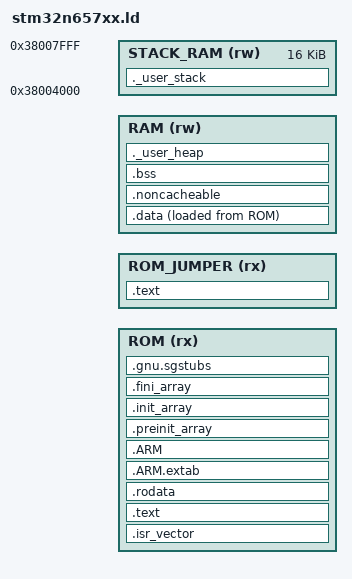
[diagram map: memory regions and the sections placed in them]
/*
******************************************************************************
**
** @file        : stm32n657xx.ld
**
** @author      : GPM Application Team
**
** @brief       : Linker script for STM32N657XX Device from STM32N6 series
**
**                Set heap size, stack size and stack location according
**                to application requirements.
**
**                Set memory bank area and size if external memory is used
**
**  Target      : STMicroelectronics STM32
**
**  Distribution: The file is distributed as is, without any warranty
**                of any kind.
**
******************************************************************************
** @attention
**
** Copyright (c) 2024 STMicroelectronics.
** All rights reserved.
**
** This software is licensed under terms that can be found in the LICENSE file
** in the root directory of this software component.
** If no LICENSE file comes with this software, it is provided AS-IS.
**
******************************************************************************
*/

#include "region_defs.h"

/* Entry Point */
ENTRY(Reset_Handler)

/* Highest address of the user mode stack */
_estack = ORIGIN(STACK_RAM) + LENGTH(STACK_RAM); /* end of "RAM" Ram type memory */
_sstack = _estack - _Min_Stack_Size;

_Min_Heap_Size = BL2_HEAP_SIZE; /* required amount of heap */
_Min_Stack_Size = BL2_MSP_STACK_SIZE; /* required amount of stack */

/* Memories definition */
MEMORY
{
  ROM  (rx)  : ORIGIN = BL2_CODE_START, LENGTH = BL2_CODE_SIZE
  ROM_JUMPER  (rx)  : ORIGIN = BL2_JUMP_CODE_START, LENGTH = BL2_JUMP_CODE_SIZE
  RAM  (rw)  : ORIGIN = BL2_DATA_START, LENGTH = BL2_DATA_SIZE
  STACK_RAM  (rw)  : ORIGIN = 0x38004000, LENGTH = 0x4000
}

/* Sections */
SECTIONS
{
  /* The startup code into "RAM" Ram type memory */
  .isr_vector :
  {
    . = ALIGN(4);
    KEEP(*(.isr_vector)) /* Startup code */
    . = ALIGN(4);
  } >ROM

  .text :
  {
    KEEP(*(.BL2_Jump_Code))
    KEEP(*(.BL2_Jump_Data))
    *stm32n6xx_hal_cortex.o (.text* .rodata*)
    *stm32n6xx_hal_mce.o (.text* .rodata*)
    *stm32n6xx_hal_bsec.o (.text* .rodata*)
    *low_level_mce.o (.text* .rodata*)
    *low_level_otp.o (.text* .rodata*)
    KEEP(*(.BL2_Error_Code))
  } >ROM_JUMPER

  /* The program code and other data into "RAM" Ram type memory */
  .text :
  {
    . = ALIGN(4);
    *(.text)           /* .text sections (code) */
    *(.text*)          /* .text* sections (code) */
    *(.glue_7)         /* glue arm to thumb code */
    *(.glue_7t)        /* glue thumb to arm code */
    *(.eh_frame)
    *(.RamFunc)        /* .RamFunc sections */
    *(.RamFunc*)       /* .RamFunc* sections */

    KEEP (*(.init))
    KEEP (*(.fini))

    . = ALIGN(4);
    _etext = .;        /* define a global symbols at end of code */
  } >ROM

  /* Constant data into "RAM" Ram type memory */
  .rodata :
  {
    . = ALIGN(4);
    *(.rodata)         /* .rodata sections (constants, strings, etc.) */
    *(.rodata*)        /* .rodata* sections (constants, strings, etc.) */
    . = ALIGN(4);
  } >ROM

  .ARM.extab   (READONLY) : /* The READONLY keyword is only supported in GCC11 and later, remove it if using GCC10 or earlier. */
   {
    . = ALIGN(4);
    *(.ARM.extab* .gnu.linkonce.armextab.*)
    . = ALIGN(4);
  } >ROM

  .ARM (READONLY) : /* The READONLY keyword is only supported in GCC11 and later, remove it if using GCC10 or earlier. */
   {
    . = ALIGN(4);
    __exidx_start = .;
    *(.ARM.exidx*)
    __exidx_end = .;
    . = ALIGN(4);
  } >ROM

  .preinit_array     (READONLY) : /* The READONLY keyword is only supported in GCC11 and later, remove it if using GCC10 or earlier. */
  {
    . = ALIGN(4);
    PROVIDE_HIDDEN (__preinit_array_start = .);
    KEEP (*(.preinit_array*))
    PROVIDE_HIDDEN (__preinit_array_end = .);
    . = ALIGN(4);
  } >ROM

  .init_array (READONLY) : /* The READONLY keyword is only supported in GCC11 and later, remove it if using GCC10 or earlier. */
  {
    . = ALIGN(4);
    PROVIDE_HIDDEN (__init_array_start = .);
    KEEP (*(SORT(.init_array.*)))
    KEEP (*(.init_array*))
    PROVIDE_HIDDEN (__init_array_end = .);
    . = ALIGN(4);
  } >ROM

  .fini_array (READONLY) : /* The READONLY keyword is only supported in GCC11 and later, remove it if using GCC10 or earlier. */
  {
    . = ALIGN(4);
    PROVIDE_HIDDEN (__fini_array_start = .);
    KEEP (*(SORT(.fini_array.*)))
    KEEP (*(.fini_array*))
    PROVIDE_HIDDEN (__fini_array_end = .);
    . = ALIGN(4);
  } >ROM

  /* Used by the startup to initialize data */
  _sidata = LOADADDR(.data);

  /* Initialized data sections into "RAM" Ram type memory */
  .data :
  {
    . = ALIGN(4);
    _sdata = .;        /* create a global symbol at data start */
    *(.data)           /* .data sections */
    *(.data*)          /* .data* sections */

    . = ALIGN(4);
    _edata = .;        /* define a global symbol at data end */

  } >RAM AT> ROM

  .noncacheable :
  {
    . = ALIGN(8);
    __snoncacheable = .;/* create symbol for start of section */
    KEEP(*(.noncacheable))
    . = ALIGN(8);
    __enoncacheable = .;  /* create symbol for end of section */
  } > RAM


  .gnu.sgstubs :
  {
    . = ALIGN(4);
    *(.gnu.sgstubs*)   /* Secure Gateway stubs */
    . = ALIGN(4);
  } >ROM
  /* Uninitialized data section into "RAM" Ram type memory */
  . = ALIGN(4);
  .bss :
  {
    /* This is used by the startup in order to initialize the .bss section */
    _sbss = .;         /* define a global symbol at bss start */
    __bss_start__ = _sbss;
    *(.bss)
    *(.bss*)
    *(COMMON)

    . = ALIGN(4);
    _ebss = .;         /* define a global symbol at bss end */
    __bss_end__ = _ebss;
  } >RAM

  /* User_heap section, used to to allocate heap memory */
  ._user_heap :
  {
    . = ALIGN(8);
    PROVIDE ( end = . );
    PROVIDE ( _end = . );
    . = . + _Min_Heap_Size;
    . = ALIGN(8);
  } >RAM

  /* User_stack section, used to allocate stack memory */
  ._user_stack :
  {
    . = ALIGN(8);
    . = . + _Min_Stack_Size;
    . = ALIGN(8);
  } >STACK_RAM

  /* Remove information from the compiler libraries */
  /DISCARD/ :
  {
    libc.a ( * )
    libm.a ( * )
    libgcc.a ( * )
  }

  .ARM.attributes 0 : { *(.ARM.attributes) }
}
